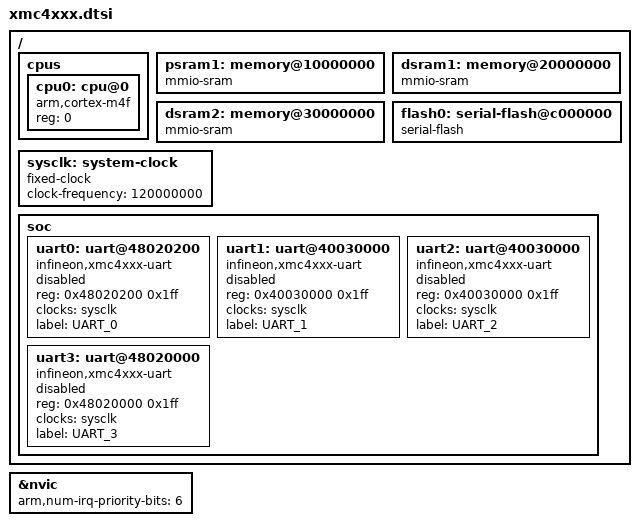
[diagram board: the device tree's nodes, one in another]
/*
 * Copyright (c) 2020 Linumiz
 * Author: Parthiban Nallathambi <parthiban@linumiz.com>
 *
 * SPDX-License-Identifier: Apache-2.0
 */

#include <arm/armv7-m.dtsi>

/ {
	cpus {
		#address-cells = <1>;
		#size-cells = <0>;

		cpu0: cpu@0 {
			compatible = "arm,cortex-m4f";
			reg = <0>;
		};
	};

	/* TODO: Add psram1 & dsram2 to MEMORY layout of linker */
	psram1: memory@10000000 {
		compatible = "mmio-sram";
	};

	dsram1: memory@20000000 {
		compatible = "mmio-sram";
	};

	dsram2: memory@30000000 {
		compatible = "mmio-sram";
	};

	flash0: serial-flash@c000000 {
		compatible = "serial-flash";
	};

	sysclk: system-clock {
		compatible = "fixed-clock";
		clock-frequency = <120000000>;
		#clock-cells = <0>;
	};

	soc {
		uart0: uart@48020200 {
			compatible = "infineon,xmc4xxx-uart";
			reg = <0x48020200 0x1ff>;
			clocks = <&sysclk>;
			label = "UART_0";
			status = "disabled";
		};

		uart1: uart@40030000 {
			compatible = "infineon,xmc4xxx-uart";
			reg = <0x40030000 0x1ff>;
			clocks = <&sysclk>;
			label = "UART_1";
			status = "disabled";
		};

		uart2: uart@40030000 {
			compatible = "infineon,xmc4xxx-uart";
			reg = <0x40030000 0x1ff>;
			clocks = <&sysclk>;
			label = "UART_2";
			status = "disabled";
		};

		uart3: uart@48020000 {
			compatible = "infineon,xmc4xxx-uart";
			reg = <0x48020000 0x1ff>;
			clocks = <&sysclk>;
			label = "UART_3";
			status = "disabled";
		};
	};
};

&nvic {
	arm,num-irq-priority-bits = <6>;
};
